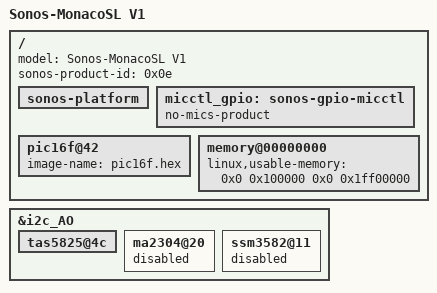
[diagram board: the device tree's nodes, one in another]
/*
 * Copyright (c) 2021, Sonos, Inc.
 *
 * SPDX-License-Identifier:     GPL-2.0
 */
/* Monaco HW versions
 *      V0 - monacosl_v0.dts		- Monaco SL v0
 *      V1 - monacosl_v1.dts		- Monaco SL v1 - Monaco pre-DVT - GPIO changes to PIC
 */
/dts-v1/;

#include "monaco_common.dtsi"

/ {
	model = "Sonos-MonacoSL V1";

	sonos-product-id = <0x0e>;

	sonos-platform {
	} ;

	micctl_gpio:sonos-gpio-micctl {
		no-mics-product;
	};

	pic16f@42 {
                image-name = "pic16f.hex";
	};

        memory@00000000 {
		linux,usable-memory = <0x0 0x100000 0x0 0x1ff00000>;
	};
}; /* end of / */

/* for mic board */
&i2c_AO {
        tas5825@4c {	// Single amp, dual-channel
		status = "okay";
	};

	ma2304@20 {	// Single amp, dual-channel
		status = "disabled";
	};

        ssm3582@11 {
		status = "disabled";
	};
};
